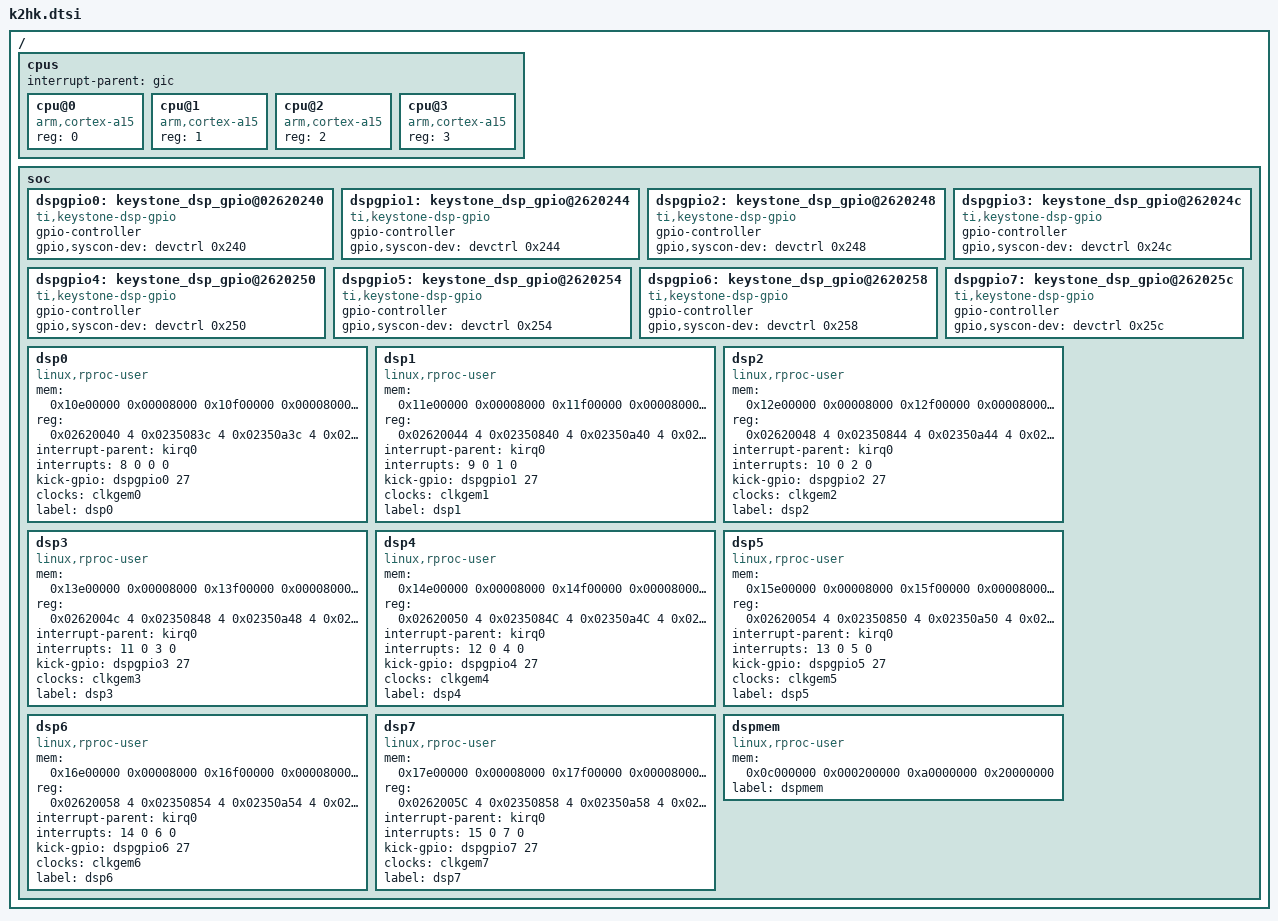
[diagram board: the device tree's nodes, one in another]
/*
 * Copyright 2013-2014 Texas Instruments, Inc.
 *
 * Keystone 2 Kepler/Hawking soc specific device tree
 *
 * This program is free software; you can redistribute it and/or modify
 * it under the terms of the GNU General Public License version 2 as
 * published by the Free Software Foundation.
 */

/ {
	cpus {
		#address-cells = <1>;
		#size-cells = <0>;

		interrupt-parent = <&gic>;

		cpu@0 {
			compatible = "arm,cortex-a15";
			device_type = "cpu";
			reg = <0>;
		};

		cpu@1 {
			compatible = "arm,cortex-a15";
			device_type = "cpu";
			reg = <1>;
		};

		cpu@2 {
			compatible = "arm,cortex-a15";
			device_type = "cpu";
			reg = <2>;
		};

		cpu@3 {
			compatible = "arm,cortex-a15";
			device_type = "cpu";
			reg = <3>;
		};
	};

	soc {
		/include/ "k2hk-clocks.dtsi"

		dspgpio0: keystone_dsp_gpio@02620240 {
			compatible = "ti,keystone-dsp-gpio";
			gpio-controller;
			#gpio-cells = <2>;
			gpio,syscon-dev = <&devctrl 0x240>;
		};

		dspgpio1: keystone_dsp_gpio@2620244 {
			compatible = "ti,keystone-dsp-gpio";
			gpio-controller;
			#gpio-cells = <2>;
			gpio,syscon-dev = <&devctrl 0x244>;
		};

		dspgpio2: keystone_dsp_gpio@2620248 {
			compatible = "ti,keystone-dsp-gpio";
			gpio-controller;
			#gpio-cells = <2>;
			gpio,syscon-dev = <&devctrl 0x248>;
		};

		dspgpio3: keystone_dsp_gpio@262024c {
			compatible = "ti,keystone-dsp-gpio";
			gpio-controller;
			#gpio-cells = <2>;
			gpio,syscon-dev = <&devctrl 0x24c>;
		};

		dspgpio4: keystone_dsp_gpio@2620250 {
			compatible = "ti,keystone-dsp-gpio";
			gpio-controller;
			#gpio-cells = <2>;
			gpio,syscon-dev = <&devctrl 0x250>;
		};

		dspgpio5: keystone_dsp_gpio@2620254 {
			compatible = "ti,keystone-dsp-gpio";
			gpio-controller;
			#gpio-cells = <2>;
			gpio,syscon-dev = <&devctrl 0x254>;
		};

		dspgpio6: keystone_dsp_gpio@2620258 {
			compatible = "ti,keystone-dsp-gpio";
			gpio-controller;
			#gpio-cells = <2>;
			gpio,syscon-dev = <&devctrl 0x258>;
		};

		dspgpio7: keystone_dsp_gpio@262025c {
			compatible = "ti,keystone-dsp-gpio";
			gpio-controller;
			#gpio-cells = <2>;
			gpio,syscon-dev = <&devctrl 0x25c>;
		};

		dsp0: dsp0 {
			compatible = "linux,rproc-user";
			mem = <0x10e00000 0x00008000
			       0x10f00000 0x00008000
			       0x10800000 0x00100000>;
			reg = <0x02620040 4
			       0x0235083c 4
			       0x02350a3c 4
			       0x02620240 4>;
			reg-names = "boot-address", "psc-mdstat", "psc-mdctl",
				"ipcgr";
			interrupt-parent = <&kirq0>;
			interrupts = <8 0 0 0>;
			kick-gpio = <&dspgpio0 27 0>;
			clocks = <&clkgem0>;
			label = "dsp0";
		};
		dsp1: dsp1 {
			compatible = "linux,rproc-user";
			mem = <0x11e00000 0x00008000
			       0x11f00000 0x00008000
			       0x11800000 0x00100000>;
			reg = <0x02620044 4
			       0x02350840 4
			       0x02350a40 4
			       0x02620244 4>;
			reg-names = "boot-address", "psc-mdstat", "psc-mdctl",
				"ipcgr";
			interrupt-parent = <&kirq0>;
			interrupts = <9 0 1 0>;
			kick-gpio = <&dspgpio1 27 0>;
			clocks = <&clkgem1>;
			label = "dsp1";
		};

		dsp2: dsp2 {
			compatible = "linux,rproc-user";
			mem = <0x12e00000 0x00008000
			       0x12f00000 0x00008000
			       0x12800000 0x00100000>;
			reg = <0x02620048 4
			       0x02350844 4
			       0x02350a44 4
			       0x02620248 4>;
			reg-names = "boot-address", "psc-mdstat", "psc-mdctl",
				"ipcgr";
			interrupt-parent = <&kirq0>;
			interrupts = <10 0 2 0>;
			kick-gpio = <&dspgpio2 27 0>;
			clocks = <&clkgem2>;
			label = "dsp2";
		};

		dsp3: dsp3 {
			compatible = "linux,rproc-user";
			mem = <0x13e00000 0x00008000
			       0x13f00000 0x00008000
			       0x13800000 0x00100000>;
			reg = <0x0262004c 4
			       0x02350848 4
			       0x02350a48 4
			       0x0262024c 4>;
			reg-names = "boot-address", "psc-mdstat", "psc-mdctl",
				"ipcgr";
			interrupt-parent = <&kirq0>;
			interrupts = <11 0 3 0>;
			kick-gpio = <&dspgpio3 27 0>;
			clocks = <&clkgem3>;
			label = "dsp3";
		};

		dsp4: dsp4 {
			compatible = "linux,rproc-user";
			mem = <0x14e00000 0x00008000
			       0x14f00000 0x00008000
			       0x14800000 0x00100000>;
			reg = <0x02620050 4
			       0x0235084C 4
			       0x02350a4C 4
			       0x02620250 4>;
			reg-names = "boot-address", "psc-mdstat", "psc-mdctl",
				"ipcgr";
			interrupt-parent = <&kirq0>;
			interrupts = <12 0 4 0>;
			kick-gpio = <&dspgpio4 27 0>;
			clocks = <&clkgem4>;
			label = "dsp4";
		};

		dsp5: dsp5 {
			compatible = "linux,rproc-user";
			mem = <0x15e00000 0x00008000
			       0x15f00000 0x00008000
			       0x15800000 0x00100000>;
			reg = <0x02620054 4
			       0x02350850 4
			       0x02350a50 4
			       0x02620254 4>;
			reg-names = "boot-address", "psc-mdstat", "psc-mdctl",
				"ipcgr";
			interrupt-parent = <&kirq0>;
			interrupts = <13 0 5 0>;
			kick-gpio = <&dspgpio5 27 0>;
			clocks = <&clkgem5>;
			label = "dsp5";
		};

		dsp6: dsp6 {
			compatible = "linux,rproc-user";
			mem = <0x16e00000 0x00008000
			       0x16f00000 0x00008000
			       0x16800000 0x00100000>;
			reg = <0x02620058 4
			       0x02350854 4
			       0x02350a54 4
			       0x02620258 4>;
			reg-names = "boot-address", "psc-mdstat", "psc-mdctl",
				"ipcgr";
			interrupt-parent = <&kirq0>;
			interrupts = <14 0 6 0>;
			kick-gpio = <&dspgpio6 27 0>;
			clocks = <&clkgem6>;
			label = "dsp6";
		};

		dsp7: dsp7 {
			compatible = "linux,rproc-user";
			mem = <0x17e00000 0x00008000
			       0x17f00000 0x00008000
			       0x17800000 0x00100000>;
			reg = <0x0262005C 4
			       0x02350858 4
			       0x02350a58 4
			       0x0262025C 4>;
			reg-names = "boot-address", "psc-mdstat", "psc-mdctl",
				"ipcgr";
			interrupt-parent = <&kirq0>;
			interrupts = <15 0 7 0>;
			kick-gpio = <&dspgpio7 27 0>;
			clocks = <&clkgem7>;
			label = "dsp7";
		};

		dspmem: dspmem {
			compatible = "linux,rproc-user";
			mem  = <0x0c000000 0x000200000
					0xa0000000 0x20000000>;
			label = "dspmem";
		};

		/include/ "k2hk-netcp.dtsi"
	};
};
